VERSION ""

NS_ :

BS_:

BU_: XXX DSU HCU EPS IPAS CGW INTERCEPTOR EON BRAKE

BO_ 32 STEER_INPUT: 8 XXX
 SG_ EPS_TORQUE : 7|16@0+ (1,0) [0|1] "" INTERCEPTOR
 SG_ STEER_ANGLE : 23|16@0+ (1,0) [0|1] "" INTERCEPTOR
 SG_ SPEED : 39|16@0+ (1,0) [0|1] "" INTERCEPTOR
 SG_ COUNTER_PEDAL : 59|4@0+ (1,0) [0|15] "" INTERCEPTOR
 SG_ CHECKSUM_PEDAL : 63|8@0+ (1,0) [0|255] "" INTERCEPTOR

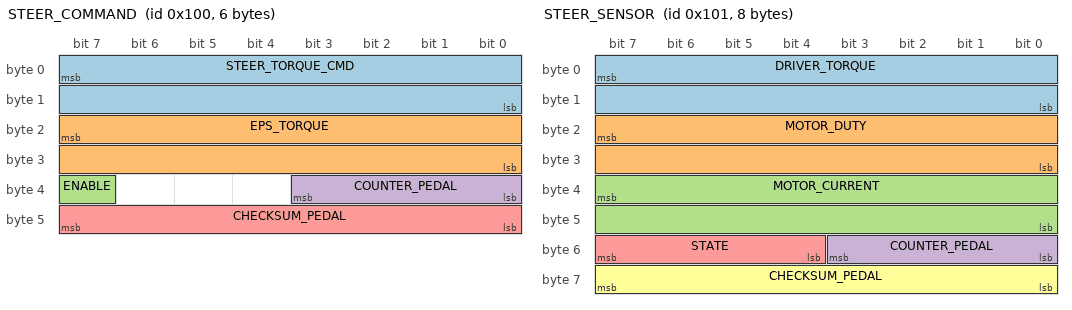
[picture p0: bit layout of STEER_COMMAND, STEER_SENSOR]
BO_ 256 STEER_COMMAND: 6 XXX
 SG_ STEER_TORQUE_CMD : 7|16@0+ (1,0) [0|1] "" INTERCEPTOR
 SG_ EPS_TORQUE : 23|16@0+ (1,0) [0|1] "" INTERCEPTOR
 SG_ ENABLE : 39|1@0+ (1,0) [0|1] "" INTERCEPTOR
 SG_ COUNTER_PEDAL : 35|4@0+ (1,0) [0|15] "" INTERCEPTOR
 SG_ CHECKSUM_PEDAL : 47|8@0+ (1,0) [0|255] "" INTERCEPTOR

BO_ 257 STEER_SENSOR: 8 XXX
 SG_ DRIVER_TORQUE : 7|16@0+ (1,0) [0|65535] "" XXX
 SG_ MOTOR_DUTY : 23|16@0+ (1,0) [0|65535] "" XXX
 SG_ MOTOR_CURRENT : 39|16@0+ (1,0) [0|65535] "" XXX
 SG_ COUNTER_PEDAL : 48|4@1+ (1,0) [0|15] "" XXX
 SG_ STATE : 55|4@0+ (1,0) [0|15] "" XXX
 SG_ CHECKSUM_PEDAL : 63|8@0+ (1,0) [0|255] "" XXX

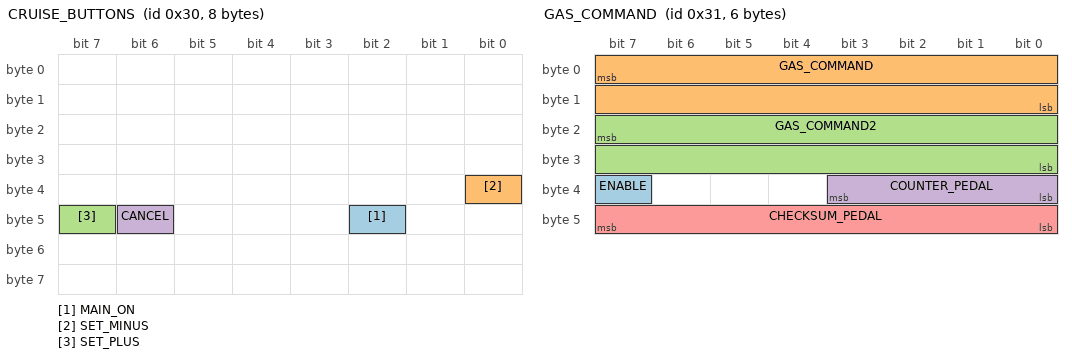
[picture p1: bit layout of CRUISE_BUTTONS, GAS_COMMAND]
BO_ 48 CRUISE_BUTTONS: 8 XXX
 SG_ MAIN_ON : 42|1@0+ (1,0) [0|1] "" XXX
 SG_ SET_MINUS : 32|1@0+ (1,0) [0|1] "" XXX
 SG_ SET_PLUS : 47|1@0+ (1,0) [0|1] "" XXX
 SG_ CANCEL : 46|1@0+ (1,0) [0|1] "" XXX

BO_ 49 GAS_COMMAND: 6 EON
 SG_ ENABLE : 39|1@0+ (1,0) [0|1] "" INTERCEPTOR
 SG_ GAS_COMMAND : 7|16@0+ (0.085,0) [0|1] "" INTERCEPTOR
 SG_ GAS_COMMAND2 : 23|16@0+ (0.17,0) [0|1] "" INTERCEPTOR
 SG_ COUNTER_PEDAL : 35|4@0+ (1,0) [0|15] "" INTERCEPTOR
 SG_ CHECKSUM_PEDAL : 47|8@0+ (1,0) [0|255] "" INTERCEPTOR

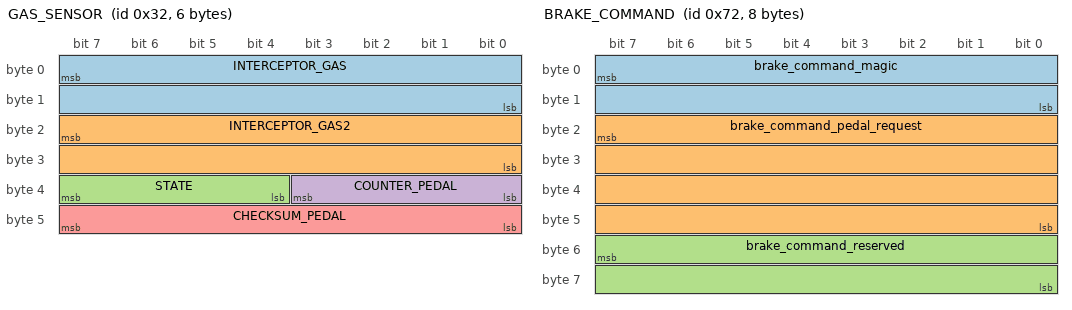
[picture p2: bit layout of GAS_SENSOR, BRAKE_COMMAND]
BO_ 50 GAS_SENSOR: 6 INTERCEPTOR
 SG_ INTERCEPTOR_GAS : 7|16@0+ (0.085,0) [0|1] "" EON
 SG_ INTERCEPTOR_GAS2 : 23|16@0+ (0.17,0) [0|1] "" EON
 SG_ STATE : 39|4@0+ (1,0) [0|15] "" EON
 SG_ COUNTER_PEDAL : 35|4@0+ (1,0) [0|15] "" EON
 SG_ CHECKSUM_PEDAL : 47|8@0+ (1,0) [0|255] "" EON

BO_ 112 BRAKE_ENABLE: 8 BRAKE
 SG_ brake_enable_magic : 7|16@0+ (1,0) [0|0] "" BRAKE
 SG_ brake_enable_reserved : 23|48@0+ (1,0) [0|0] "" BRAKE

BO_ 113 BRAKE_DISABLE: 8 BRAKE
 SG_ brake_disable_magic : 7|16@0+ (1,0) [0|0] "" BRAKE
 SG_ brake_disable_reserved : 23|48@0+ (1,0) [0|0] "" BRAKE

BO_ 114 BRAKE_COMMAND: 8 BRAKE
 SG_ brake_command_magic : 7|16@0+ (1,0) [0|0] "" BRAKE
 SG_ brake_command_pedal_request : 23|32@0+ (1,0) [0|1] "" BRAKE
 SG_ brake_command_reserved : 55|16@0+ (1,0) [0|0] "" BRAKE

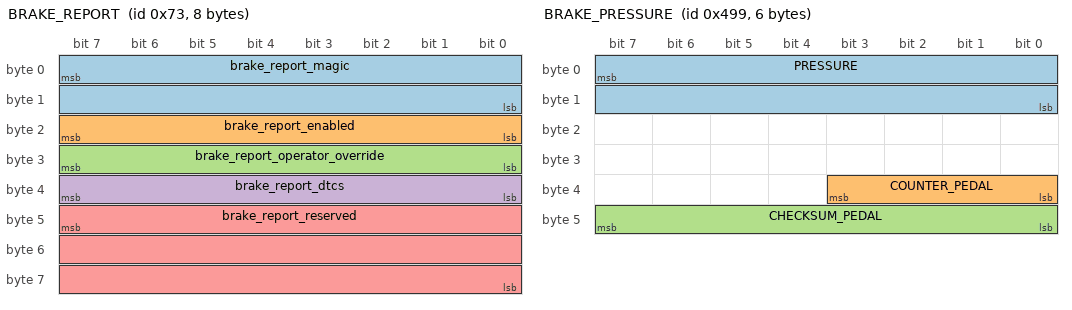
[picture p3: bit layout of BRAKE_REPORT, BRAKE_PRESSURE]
BO_ 115 BRAKE_REPORT: 8 BRAKE
 SG_ brake_report_magic : 7|16@0+ (1,0) [0|0] "" BRAKE
 SG_ brake_report_enabled : 23|8@0+ (1,0) [0|0] "" BRAKE
 SG_ brake_report_operator_override : 31|8@0+ (1,0) [0|0] "" BRAKE
 SG_ brake_report_dtcs : 39|8@0+ (1,0) [0|0] "" BRAKE
 SG_ brake_report_reserved : 47|24@0+ (1,0) [0|0] "" BRAKE

BO_ 1177 BRAKE_PRESSURE: 6 EON
 SG_ PRESSURE : 7|16@0+ (1,0) [0|1] "" INTERCEPTOR
 SG_ COUNTER_PEDAL : 35|4@0+ (1,0) [0|15] "" INTERCEPTOR
 SG_ CHECKSUM_PEDAL : 47|8@0+ (1,0) [0|255] "" INTERCEPTOR

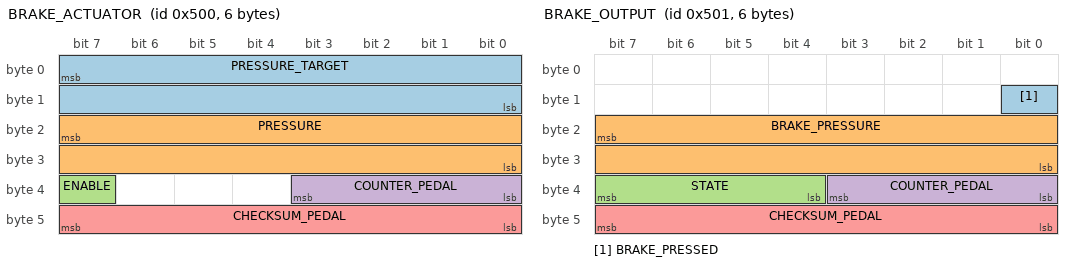
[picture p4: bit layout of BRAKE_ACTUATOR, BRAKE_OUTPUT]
BO_ 1280 BRAKE_ACTUATOR: 6 EON
 SG_ PRESSURE_TARGET : 7|16@0+ (1,0) [0|1] "" INTERCEPTOR
 SG_ PRESSURE : 23|16@0+ (1,0) [0|1] "" INTERCEPTOR
 SG_ ENABLE : 39|1@0+ (1,0) [0|1] "" INTERCEPTOR
 SG_ COUNTER_PEDAL : 35|4@0+ (1,0) [0|15] "" INTERCEPTOR
 SG_ CHECKSUM_PEDAL : 47|8@0+ (1,0) [0|255] "" INTERCEPTOR

BO_ 1281 BRAKE_OUTPUT: 6 INTERCEPTOR
 SG_ BRAKE_PRESSED : 8|1@0+ (1,0) [0|1] "" EON
 SG_ BRAKE_PRESSURE : 23|16@0+ (1,0) [0|1] "" EON
 SG_ STATE : 39|4@0+ (1,0) [0|15] "" EON
 SG_ COUNTER_PEDAL : 35|4@0+ (1,0) [0|15] "" EON
 SG_ CHECKSUM_PEDAL : 47|8@0+ (1,0) [0|255] "" EON

BO_ 176 STEER_ANGLE_SENSOR: 8 XXX
 SG_ STEER_ANGLE : 46|15@0- (0.044444444,0) [0|65535] "" XXX

BO_ 320 STEER_TORQUE: 8 XXX
 SG_ DIRECTION : 21|1@0+ (1,0) [0|1] "" XXX
 SG_ DRIVER_TORQUE : 16|9@0+ (1,0) [0|16383] "" XXX

BO_ 128 GAS_BRAKE: 8 XXX
 SG_ BRAKE_PRESSED : 2|1@0+ (1,0) [0|511] "" XXX
 SG_ GAS_PEDAL : 1|10@0+ (1,0) [0|255] "" XXX

BO_ 864 DOORS: 8 XXX
 SG_ DRIVER_DOOR : 16|1@0+ (1,0) [0|1] "" XXX

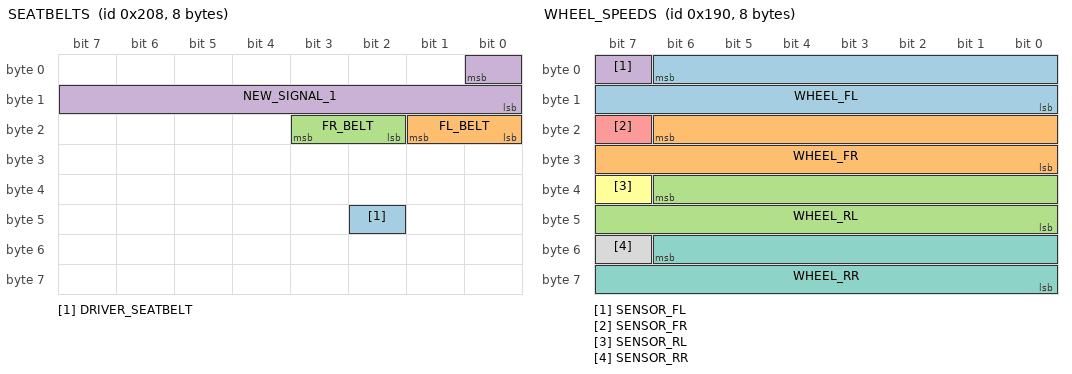
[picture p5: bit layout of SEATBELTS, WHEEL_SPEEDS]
BO_ 520 SEATBELTS: 8 XXX
 SG_ DRIVER_SEATBELT : 42|1@0+ (1,0) [0|1] "" XXX
 SG_ FL_BELT : 17|2@0+ (1,0) [0|3] "" XXX
 SG_ FR_BELT : 19|2@0+ (1,0) [0|3] "" XXX
 SG_ NEW_SIGNAL_1 : 0|9@0- (1,0) [0|511] "" XXX

BO_ 448 BRAKE_MODULE: 8 XXX
 SG_ BRAKE_PRESSURE : 51|12@0+ (1,0) [0|63] "" XXX

BO_ 400 WHEEL_SPEEDS: 8 XXX
 SG_ WHEEL_FL : 6|15@0+ (0.01,0) [0|65535] "" XXX
 SG_ WHEEL_FR : 22|15@0+ (0.01,0) [0|65535] "" XXX
 SG_ WHEEL_RL : 38|15@0+ (0.01,0) [0|65535] "" XXX
 SG_ SENSOR_FL : 7|1@0+ (1,0) [0|1] "" XXX
 SG_ SENSOR_FR : 23|1@0+ (1,0) [0|1] "" XXX
 SG_ SENSOR_RL : 39|1@0+ (1,0) [0|1] "" XXX
 SG_ WHEEL_RR : 54|15@0+ (0.01,0) [0|65535] "" XXX
 SG_ SENSOR_RR : 55|1@0+ (1,0) [0|1] "" XXX

BO_ 16 VSC: 8 XXX
 SG_ STEER_RATE : 35|12@0+ (0.05,0) [0|63] "" XXX

BO_ 224 GEAR_PACKET: 8 XXX
 SG_ GEAR : 37|3@0+ (1,0) [0|7] "" XXX

CM_ SG_ 224 GEAR "0=P, 1=R, 2=N, 3=D, 4= S";
VAL_ 257 STATE 7 "FAULT_SENSOR" 6 "FAULT_INVALID" 5 "FAULT_TIMEOUT" 4 "FAULT_STARTUP" 3 "FAULT_SCE" 2 "FAULT_SEND" 1 "FAULT_BAD_CHECKSUM" 0 "NO_FAULT" ;
VAL_ 1281 STATE 5 "FAULT_TIMEOUT" 4 "FAULT_STARTUP" 3 "FAULT_SCE" 2 "FAULT_SEND" 1 "FAULT_BAD_CHECKSUM" 0 "NO_FAULT" ;
